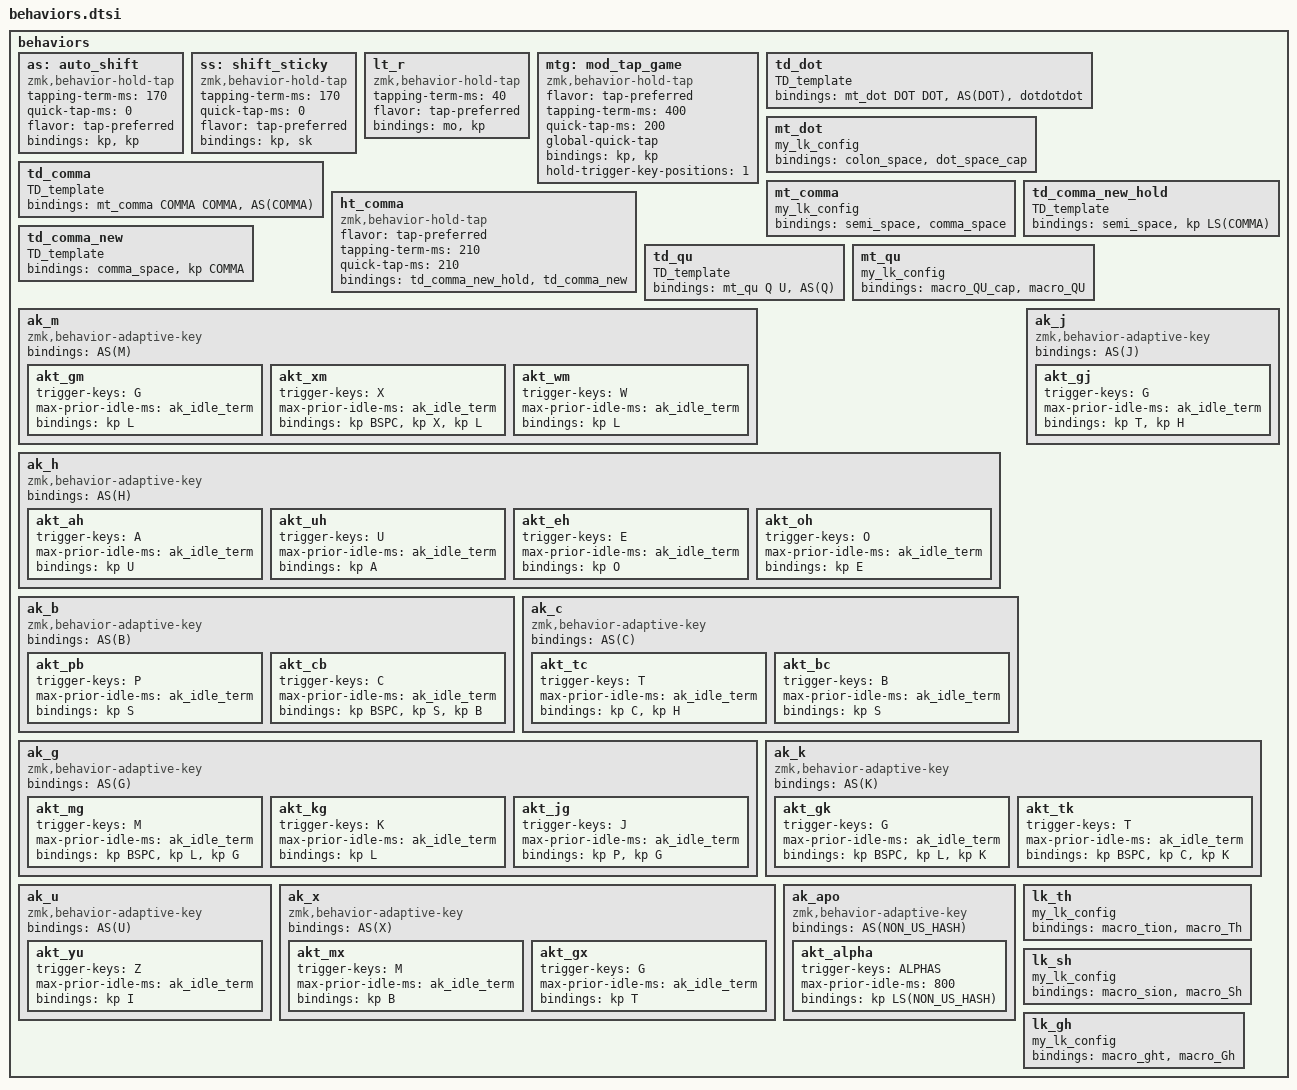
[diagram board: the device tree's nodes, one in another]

#define my_tapping_term 150
#define ak_idle_term 200

#define TD_template compatible = "zmk,behavior-tap-dance"; #binding-cells = <0>; tapping-term-ms = <200>
#define ALPHAS A B C D E F G H I J H K L M N O P Q R S T U V W X Y Z

#define     my_hrm_config \
            compatible = "zmk,behavior-hold-tap"; \
            #binding-cells = <2>; \
            flavor = "balanced"; \
            hold-trigger-on-release; \
            tapping-term-ms = <my_tapping_term>; \
            quick-tap-ms = <my_quick_tapping_term>

#define     my_lk_config \
            compatible = "zmk,behavior-hold-tap"; \
            #binding-cells = <2>; \
            tapping-term-ms = <my_tapping_term>; \
            flavor = "tap-preferred"


behaviors {
    as: auto_shift {
            compatible = "zmk,behavior-hold-tap";
            #binding-cells = <2>;
            tapping-term-ms = <170>;
            quick-tap-ms = <0>;
            flavor = "tap-preferred";
            bindings = <&kp>, <&kp>; 
        };

    ss: shift_sticky {
            compatible = "zmk,behavior-hold-tap";
            #binding-cells = <2>;
            tapping-term-ms = <170>;
            quick-tap-ms = <0>;
            flavor = "tap-preferred";
            bindings = <&kp>, <&sk>; 
        };

    lt_r: lt_r {
            compatible = "zmk,behavior-hold-tap";
            #binding-cells = <2>;
            tapping-term-ms = <40>;
            // quick-tap-ms = <0>;
            flavor = "tap-preferred";
            bindings = <&mo>, <&kp>; 
        };

    mtg: mod_tap_game {
        compatible = "zmk,behavior-hold-tap";
        #binding-cells = <2>;
        flavor = "tap-preferred";
        tapping-term-ms = <400>;
        quick-tap-ms = <200>;
        global-quick-tap;
        bindings = <&kp>, <&kp>;
        hold-trigger-key-positions = <1>;    // <---[[the W key]]
    };

    // tog_on: toggle_layer_on_only {
    //         compatible = "zmk,behavior-toggle-layer";
    //         #binding-cells = <1>;
    //         display-name = "Toggle Layer On";
    //         toggle-mode = "on";
    //     };
    //
    // TAP DANCE
    //
    td_dot: td_dot {
        TD_template;
        bindings = <&mt_dot DOT DOT>
                 , <AS(DOT)>
                 , <&dotdotdot>;
    };

    mt_dot: mt_dot {
            my_lk_config;
            bindings = <&colon_space>, <&dot_space_cap>;
        };


    
    //new
    td_comma: td_comma {
        TD_template;
        bindings = <&mt_comma COMMA COMMA>
                 , <AS(COMMA)>;
    };

    mt_comma: mt_comma {
            my_lk_config;
            bindings = <&semi_space>, <&comma_space>;
        };
    //
    ht_comma: ht_comma {
        compatible = "zmk,behavior-hold-tap";
        #binding-cells = <2>;
        flavor = "tap-preferred";
        tapping-term-ms = <210>;
        quick-tap-ms = <210>;
        bindings = <&td_comma_new_hold>, <&td_comma_new>;
        // retro-tap;        
    }; 

    td_comma_new_hold: td_comma_new_hold{
        TD_template;
        bindings = <&semi_space>
                 , <&kp LS(COMMA)>;
    };

    td_comma_new: td_comma_new {
        TD_template;
        bindings = <&comma_space>
                 , <&kp COMMA>;
    };


    // td_space_ctrl: td_space_ctrl {
    //     compatible = "zmk,behavior-tap-dance";
    //     #binding-cells = <0>;
    //     tapping-term-ms = <200>;
    //     bindings = <&kp SPACE>, <&kp LCTRL>;
    // };

    // htd_kp_space_ctrl: htd_kp_space_ctrl {
    //     compatible = "zmk,behavior-hold-tap";
    //     #binding-cells = <2>;
    //     flavor = "tap-preferred";
    //     tapping-term-ms = <200>;
    //     quick-tap-ms = <200>;
    //     bindings = <&kp>, <&td_space_ctrl>;
    //     hold-trigger-key-positions = <KB_THUMBS KB_RIGHT>;
    //     retro-tap;
    // };

    // new end

    td_qu: td_qu {
            TD_template;
            bindings = <&mt_qu Q U>
                    , <AS(Q)>;
        };

    mt_qu: mt_qu {
            my_lk_config;
            bindings = <&macro_QU_cap>, <&macro_QU>;
        };



// ----- LAYER
    // td_r: td_r{
    //     compatible = "zmk,behavior-tap-dance";
    //     #binding-cells = <0>;
    //     tapping-term-ms = <185>;
    //     bindings = <&lt_r l_L R>
    //              , <&kp LS(R)>;
    // };

    // Adaptive Keys

    // M turns to L After X,W,G. 
    // G turns previous to L for M. MG->GL
    // G turns to L before and after K, GK->LK KG->KL
    // J expands G -> GTH,
    // H switches row for A,U,E,O
    // B and C -> BS, SB  B stands for S
    // B after P -> PS
    // C after T expands -> TCH
    // TK turns to C before K -> CK
    // U turns to I after Y (de)  


    ak_m: ak_m { // becomes L M->L: for G,X,W
        compatible = "zmk,behavior-adaptive-key";
        #binding-cells = <0>;
        bindings = <AS(M)>;

        akt_gm { trigger-keys = <G>; max-prior-idle-ms = <ak_idle_term>; bindings = <&kp L>; };
        akt_xm { trigger-keys = <X>; max-prior-idle-ms = <ak_idle_term>; bindings = <&kp BSPC &kp X &kp L>; };
        akt_wm { trigger-keys = <W>; max-prior-idle-ms = <ak_idle_term>; bindings = <&kp L>; };
    };

    ak_h: ak_h { // switches top and bottom row: A<-H->U,E<-H->O
        compatible = "zmk,behavior-adaptive-key";
        #binding-cells = <0>;
        bindings = <AS(H)>;

        akt_ah { trigger-keys = <A>; max-prior-idle-ms = <ak_idle_term>; bindings = <&kp U>; };
        akt_uh { trigger-keys = <U>; max-prior-idle-ms = <ak_idle_term>; bindings = <&kp A>; };
        akt_eh { trigger-keys = <E>; max-prior-idle-ms = <ak_idle_term>; bindings = <&kp O>; };
        akt_oh { trigger-keys = <O>; max-prior-idle-ms = <ak_idle_term>; bindings = <&kp E>; };
    };

    ak_b: ak_b { // raises to PB->PS. BC -> BS, CB->SB
        compatible = "zmk,behavior-adaptive-key";
        #binding-cells = <0>;
        bindings = <AS(B)>;

        akt_pb { trigger-keys = <P>; max-prior-idle-ms = <ak_idle_term>; bindings = <&kp S>; };
        akt_cb { trigger-keys = <C>; max-prior-idle-ms = <ak_idle_term>; bindings = <&kp BSPC &kp S &kp B>; };
    };

    ak_c: ak_c { // expands TC-> TCH, CB->SB (see above)
        compatible = "zmk,behavior-adaptive-key";
        #binding-cells = <0>;
        bindings = <AS(C)>;

        akt_tc { trigger-keys = <T>; max-prior-idle-ms = <ak_idle_term>; bindings = <&kp C &kp H>; };
        akt_bc { trigger-keys = <B>; max-prior-idle-ms = <ak_idle_term>; bindings = <&kp S>; };
    };

    ak_g: ak_g { // MG -> LG,  KG -> KL, JPG macro, 
        compatible = "zmk,behavior-adaptive-key";
        #binding-cells = <0>;
        bindings = <AS(G)>;

        akt_mg { trigger-keys = <M>; max-prior-idle-ms = <ak_idle_term>; bindings = <&kp BSPC &kp L &kp G>; };
        akt_kg { trigger-keys = <K>; max-prior-idle-ms = <ak_idle_term>; bindings = <&kp L>; };
        akt_jg { trigger-keys = <J>; max-prior-idle-ms = <ak_idle_term>; bindings = <&kp P &kp G>; }; //jpg
    };

    ak_j: ak_j { // expands GJ-> GTH, WJ->WL
        compatible = "zmk,behavior-adaptive-key";
        #binding-cells = <0>;
        bindings = <AS(J)>;

        akt_gj { trigger-keys = <G>; max-prior-idle-ms = <ak_idle_term>; bindings = <&kp T &kp H>; };
        // akt_wj { trigger-keys = <W>; max-prior-idle-ms = <ak_idle_term>; bindings = <&kp L>; };
    };

    ak_k: ak_k { // GK->LK, TK->CK
        compatible = "zmk,behavior-adaptive-key";
        #binding-cells = <0>;
        bindings = <AS(K)>;

        akt_gk { trigger-keys = <G>; max-prior-idle-ms = <ak_idle_term>; bindings = <&kp BSPC &kp L &kp K>; };
        akt_tk { trigger-keys = <T>; max-prior-idle-ms = <ak_idle_term>; bindings = <&kp BSPC &kp C &kp K >; };
    };

    ak_u: ak_u {// YU-> YI
        compatible = "zmk,behavior-adaptive-key";
        #binding-cells = <0>;
        bindings = <AS(U)>;

        akt_yu { trigger-keys = <Z>; max-prior-idle-ms = <ak_idle_term>; bindings = <&kp I>; };
    };

    ak_x: ak_x { // GX->GT, MX->MB
        compatible = "zmk,behavior-adaptive-key";
        #binding-cells = <0>;
        bindings = <AS(X)>;

        akt_mx { trigger-keys = <M>; max-prior-idle-ms = <ak_idle_term>; bindings = <&kp B>; };
        akt_gx { trigger-keys = <G>; max-prior-idle-ms = <ak_idle_term>; bindings = <&kp T >; };
    };

    ak_apo: ak_apo { // # becomes '
        compatible = "zmk,behavior-adaptive-key";
        #binding-cells = <0>;
        bindings = <AS(NON_US_HASH)>;

        akt_alpha { trigger-keys = <ALPHAS>; max-prior-idle-ms = <800>; bindings = <&kp LS(NON_US_HASH)>; };
    };
    //
    // Digraphs
    //
    lk_th: lk_th { // Th on tap, tion on "linger"
        my_lk_config;
        bindings = <&macro_tion>, <&macro_Th>;
    };
    lk_sh: lk_sh { // Sh on tap, sion on "linger"
        my_lk_config;
        bindings = <&macro_sion>, <&macro_Sh>;
    };
    lk_gh: lk_gh { // Gh on tap, Ght on "linger"
        my_lk_config;
        bindings = <&macro_ght>, <&macro_Gh>;
    };

    //
    // linger keys
    //

};
